# jbr_MDR1986VE1T register map
Registers are 32-bit, access not given, no defined reset value unless marked. A register's access mark holds for its fields unless they carry their own. Addresses are absolute; registers are grouped by the start of their names; [hi:lo] are bit positions; {n}, {i} and the like mark numbered series; 'fields as' and 'values as' point back to an identical list.

## TIM1
0x40070000 TIM1_CNT
0x40070004 TIM1_PSG
  [15:0] PSG
0x40070008 TIM1_ARR
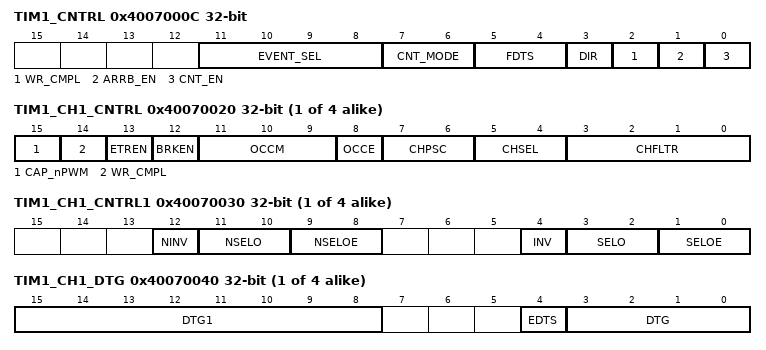
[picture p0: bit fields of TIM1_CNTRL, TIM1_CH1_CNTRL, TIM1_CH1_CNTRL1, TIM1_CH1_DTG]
0x4007000C TIM1_CNTRL
  [11:8] EVENT_SEL, [7:6] CNT_MODE, [5:4] FDTS, [3] DIR, [2] WR_CMPL, [1] ARRB_EN, [0] CNT_EN
{0x4007000C+4i} TIM1_CCR{i} (i=1..4)
  [31:0] CCR
{0x4007001C+4i} TIM1_CH{i}_CNTRL (i=1..4)
  [15] CAP_nPWM, [14] WR_CMPL, [13] ETREN, [12] BRKEN, [11:9] OCCM, [8] OCCE, [7:6] CHPSC, [5:4] CHSEL, [3:0] CHFLTR
{0x4007002C+4i} TIM1_CH{i}_CNTRL1 (i=1..4)
  [12] NINV, [11:10] NSELO, [9:8] NSELOE, [4] INV, [3:2] SELO, [1:0] SELOE
{0x4007003C+4i} TIM1_CH{i}_DTG (i=1..4)
  [15:8] DTG1, [4] EDTS, [3:0] DTG
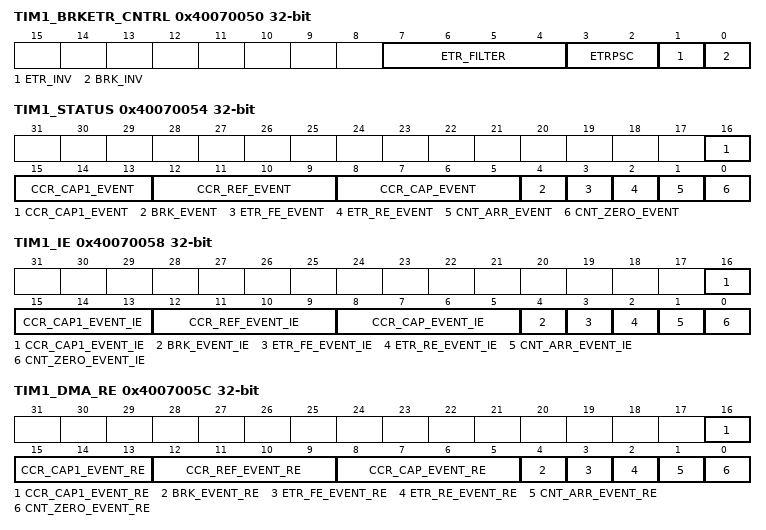
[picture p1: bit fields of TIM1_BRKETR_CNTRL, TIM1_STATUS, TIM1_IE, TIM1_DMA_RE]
0x40070050 TIM1_BRKETR_CNTRL
  [7:4] ETR_FILTER, [3:2] ETRPSC, [1] ETR_INV, [0] BRK_INV
0x40070054 TIM1_STATUS
  [16:13] CCR_CAP1_EVENT, [12:9] CCR_REF_EVENT, [8:5] CCR_CAP_EVENT, [4] BRK_EVENT, [3] ETR_FE_EVENT, [2] ETR_RE_EVENT, [1] CNT_ARR_EVENT, [0] CNT_ZERO_EVENT
0x40070058 TIM1_IE
  [16:13] CCR_CAP1_EVENT_IE, [12:9] CCR_REF_EVENT_IE, [8:5] CCR_CAP_EVENT_IE, [4] BRK_EVENT_IE, [3] ETR_FE_EVENT_IE, [2] ETR_RE_EVENT_IE, [1] CNT_ARR_EVENT_IE, [0] CNT_ZERO_EVENT_IE
0x4007005C TIM1_DMA_RE
  [16:13] CCR_CAP1_EVENT_RE, [12:9] CCR_REF_EVENT_RE, [8:5] CCR_CAP_EVENT_RE, [4] BRK_EVENT_RE, [3] ETR_FE_EVENT_RE, [2] ETR_RE_EVENT_RE, [1] CNT_ARR_EVENT_RE, [0] CNT_ZERO_EVENT_RE
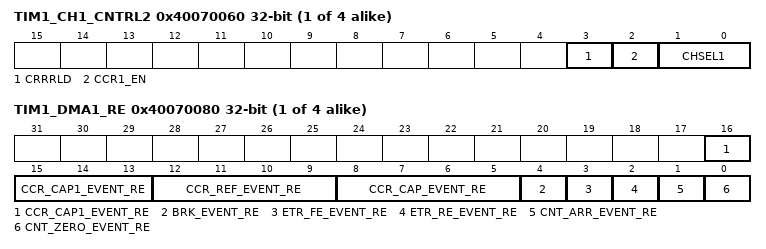
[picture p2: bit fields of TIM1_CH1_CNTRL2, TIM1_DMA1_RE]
{0x4007005C+4i} TIM1_CH{i}_CNTRL2 (i=1..4)
  [3] CRRRLD, [2] CCR1_EN, [1:0] CHSEL1
0x40070070 TIM1_CCR11
  [31:0] CCR1
0x40070074 TIM1_CCR21
  [31:0] CCR1
0x40070078 TIM1_CCR31
  [31:0] CCR1
0x4007007C TIM1_CCR41
  [31:0] CCR1
{0x4007007C+4i} TIM1_DMA{i}_RE (i=1..4)
  fields as TIM1_DMA_RE

## TIM2
0x40078000 TIM2_CNT
0x40078004 TIM2_PSG
  [15:0] PSG
0x40078008 TIM2_ARR
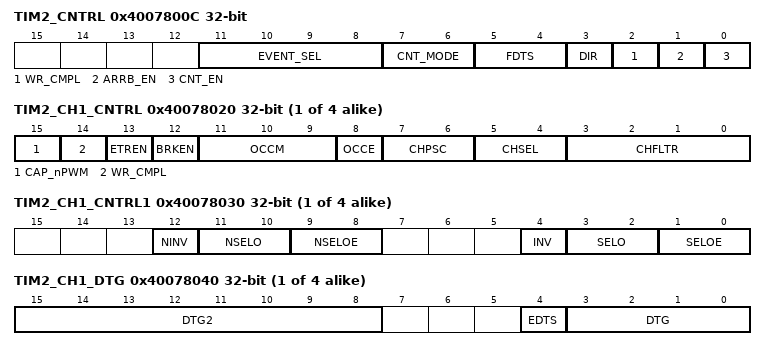
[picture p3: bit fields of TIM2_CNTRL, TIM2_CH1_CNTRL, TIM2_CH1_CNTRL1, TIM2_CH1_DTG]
0x4007800C TIM2_CNTRL
  [11:8] EVENT_SEL, [7:6] CNT_MODE, [5:4] FDTS, [3] DIR, [2] WR_CMPL, [1] ARRB_EN, [0] CNT_EN
{0x4007800C+4i} TIM2_CCR{i} (i=1..4)
  [31:0] CCR
{0x4007801C+4i} TIM2_CH{i}_CNTRL (i=1..4)
  [15] CAP_nPWM, [14] WR_CMPL, [13] ETREN, [12] BRKEN, [11:9] OCCM, [8] OCCE, [7:6] CHPSC, [5:4] CHSEL, [3:0] CHFLTR
{0x4007802C+4i} TIM2_CH{i}_CNTRL1 (i=1..4)
  [12] NINV, [11:10] NSELO, [9:8] NSELOE, [4] INV, [3:2] SELO, [1:0] SELOE
{0x4007803C+4i} TIM2_CH{i}_DTG (i=1..4)
  [15:8] DTG2, [4] EDTS, [3:0] DTG
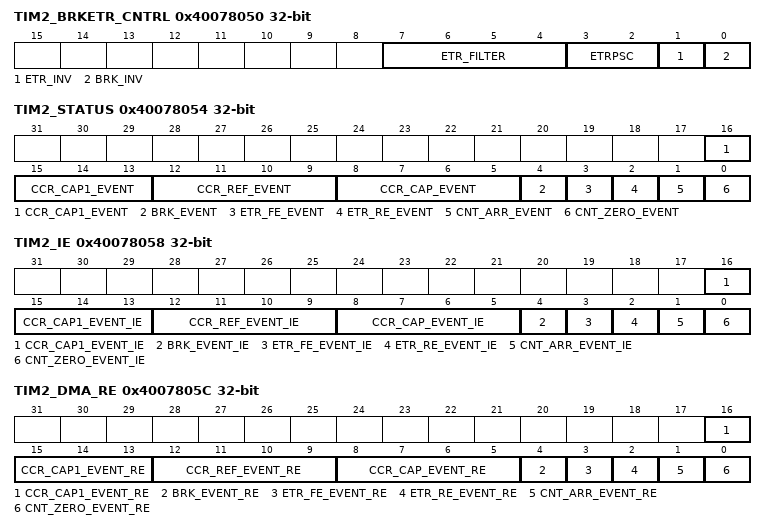
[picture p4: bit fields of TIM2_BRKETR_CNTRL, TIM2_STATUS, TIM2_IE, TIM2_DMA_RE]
0x40078050 TIM2_BRKETR_CNTRL
  [7:4] ETR_FILTER, [3:2] ETRPSC, [1] ETR_INV, [0] BRK_INV
0x40078054 TIM2_STATUS
  [16:13] CCR_CAP1_EVENT, [12:9] CCR_REF_EVENT, [8:5] CCR_CAP_EVENT, [4] BRK_EVENT, [3] ETR_FE_EVENT, [2] ETR_RE_EVENT, [1] CNT_ARR_EVENT, [0] CNT_ZERO_EVENT
0x40078058 TIM2_IE
  [16:13] CCR_CAP1_EVENT_IE, [12:9] CCR_REF_EVENT_IE, [8:5] CCR_CAP_EVENT_IE, [4] BRK_EVENT_IE, [3] ETR_FE_EVENT_IE, [2] ETR_RE_EVENT_IE, [1] CNT_ARR_EVENT_IE, [0] CNT_ZERO_EVENT_IE
0x4007805C TIM2_DMA_RE
  [16:13] CCR_CAP1_EVENT_RE, [12:9] CCR_REF_EVENT_RE, [8:5] CCR_CAP_EVENT_RE, [4] BRK_EVENT_RE, [3] ETR_FE_EVENT_RE, [2] ETR_RE_EVENT_RE, [1] CNT_ARR_EVENT_RE, [0] CNT_ZERO_EVENT_RE
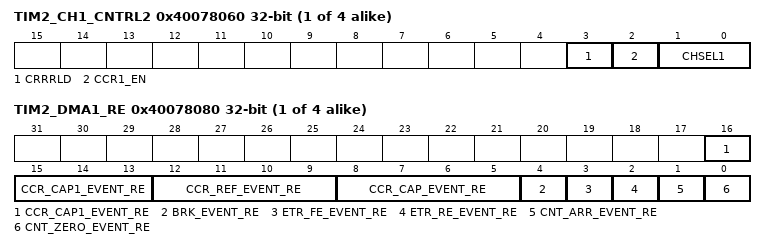
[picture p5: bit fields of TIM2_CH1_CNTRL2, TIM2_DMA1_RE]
{0x4007805C+4i} TIM2_CH{i}_CNTRL2 (i=1..4)
  [3] CRRRLD, [2] CCR1_EN, [1:0] CHSEL1
0x40078070 TIM2_CCR11
  [31:0] CCR1
0x40078074 TIM2_CCR21
  [31:0] CCR1
0x40078078 TIM2_CCR31
  [31:0] CCR1
0x4007807C TIM2_CCR41
  [31:0] CCR1
{0x4007807C+4i} TIM2_DMA{i}_RE (i=1..4)
  fields as TIM2_DMA_RE

## TIM3
0x40080000 TIM3_CNT
0x40080004 TIM3_PSG
  [15:0] PSG
0x40080008 TIM3_ARR
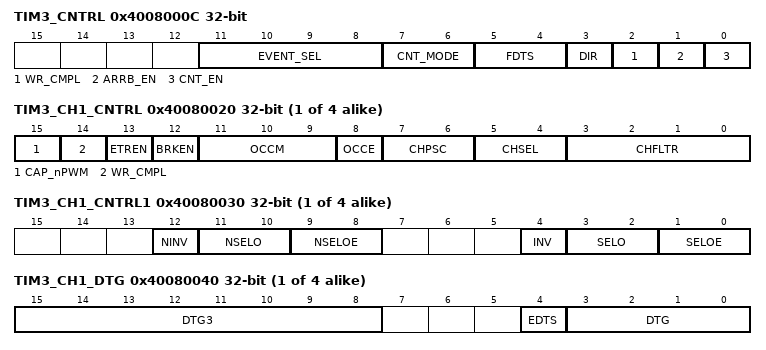
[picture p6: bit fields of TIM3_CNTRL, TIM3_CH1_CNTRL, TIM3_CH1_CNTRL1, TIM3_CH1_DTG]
0x4008000C TIM3_CNTRL
  [11:8] EVENT_SEL, [7:6] CNT_MODE, [5:4] FDTS, [3] DIR, [2] WR_CMPL, [1] ARRB_EN, [0] CNT_EN
{0x4008000C+4i} TIM3_CCR{i} (i=1..4)
  [31:0] CCR
{0x4008001C+4i} TIM3_CH{i}_CNTRL (i=1..4)
  [15] CAP_nPWM, [14] WR_CMPL, [13] ETREN, [12] BRKEN, [11:9] OCCM, [8] OCCE, [7:6] CHPSC, [5:4] CHSEL, [3:0] CHFLTR
{0x4008002C+4i} TIM3_CH{i}_CNTRL1 (i=1..4)
  [12] NINV, [11:10] NSELO, [9:8] NSELOE, [4] INV, [3:2] SELO, [1:0] SELOE
{0x4008003C+4i} TIM3_CH{i}_DTG (i=1..4)
  [15:8] DTG3, [4] EDTS, [3:0] DTG
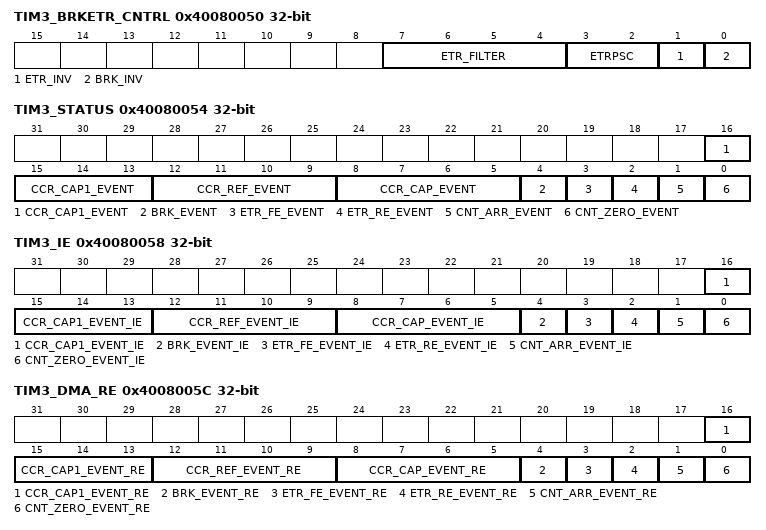
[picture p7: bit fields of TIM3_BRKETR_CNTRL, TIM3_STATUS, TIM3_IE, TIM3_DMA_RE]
0x40080050 TIM3_BRKETR_CNTRL
  [7:4] ETR_FILTER, [3:2] ETRPSC, [1] ETR_INV, [0] BRK_INV
0x40080054 TIM3_STATUS
  [16:13] CCR_CAP1_EVENT, [12:9] CCR_REF_EVENT, [8:5] CCR_CAP_EVENT, [4] BRK_EVENT, [3] ETR_FE_EVENT, [2] ETR_RE_EVENT, [1] CNT_ARR_EVENT, [0] CNT_ZERO_EVENT
0x40080058 TIM3_IE
  [16:13] CCR_CAP1_EVENT_IE, [12:9] CCR_REF_EVENT_IE, [8:5] CCR_CAP_EVENT_IE, [4] BRK_EVENT_IE, [3] ETR_FE_EVENT_IE, [2] ETR_RE_EVENT_IE, [1] CNT_ARR_EVENT_IE, [0] CNT_ZERO_EVENT_IE
0x4008005C TIM3_DMA_RE
  [16:13] CCR_CAP1_EVENT_RE, [12:9] CCR_REF_EVENT_RE, [8:5] CCR_CAP_EVENT_RE, [4] BRK_EVENT_RE, [3] ETR_FE_EVENT_RE, [2] ETR_RE_EVENT_RE, [1] CNT_ARR_EVENT_RE, [0] CNT_ZERO_EVENT_RE
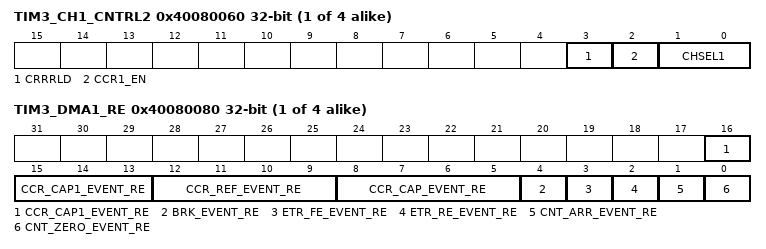
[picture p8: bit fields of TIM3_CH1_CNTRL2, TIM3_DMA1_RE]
{0x4008005C+4i} TIM3_CH{i}_CNTRL2 (i=1..4)
  [3] CRRRLD, [2] CCR1_EN, [1:0] CHSEL1
0x40080070 TIM3_CCR11
  [31:0] CCR1
0x40080074 TIM3_CCR21
  [31:0] CCR1
0x40080078 TIM3_CCR31
  [31:0] CCR1
0x4008007C TIM3_CCR41
  [31:0] CCR1
{0x4008007C+4i} TIM3_DMA{i}_RE (i=1..4)
  fields as TIM3_DMA_RE
